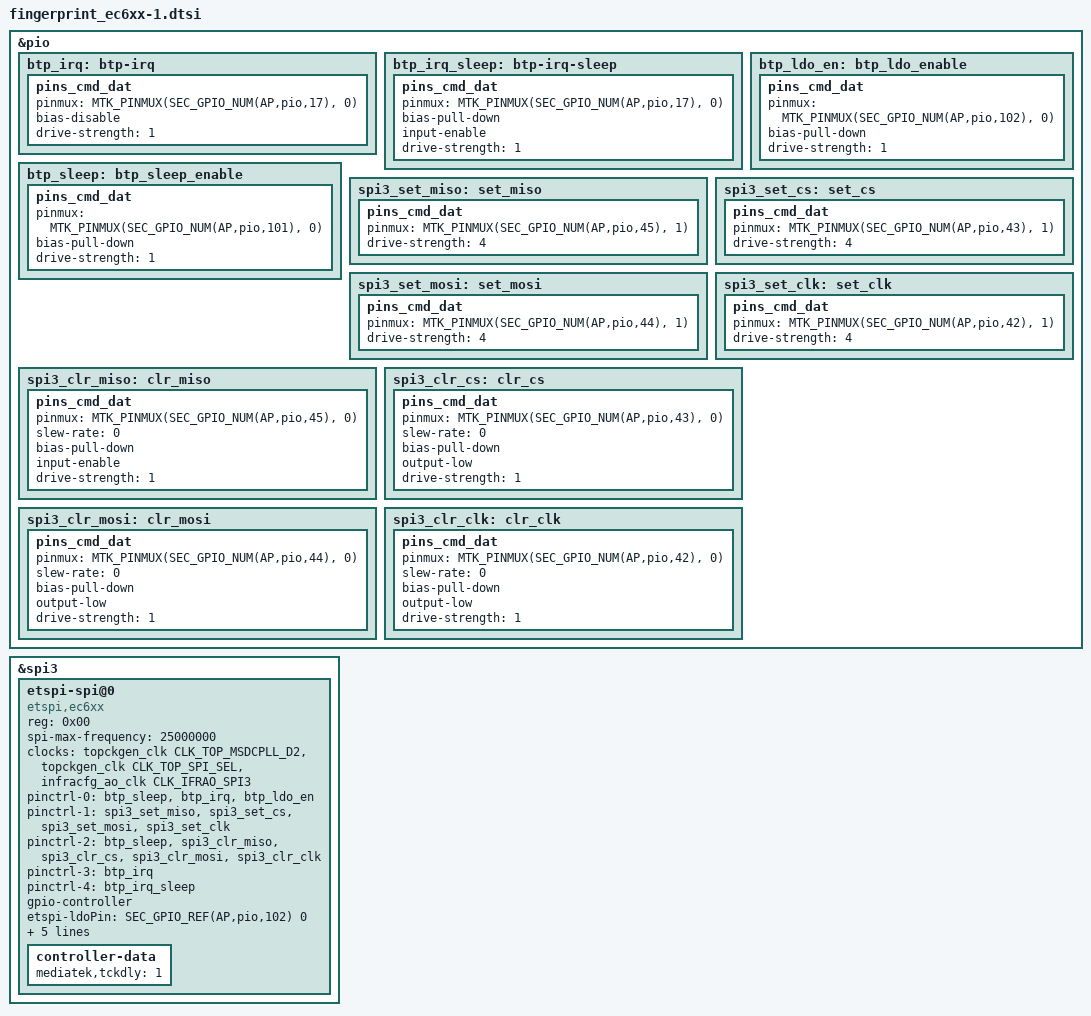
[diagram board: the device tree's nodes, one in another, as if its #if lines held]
/*
 * Copyright (c) 2022, The Linux Foundation. All rights reserved.
 *
 * This program is free software; you can redistribute it and/or modify
 * it under the terms of the GNU General Public License version 2 and
 * only version 2 as published by the Free Software Foundation.
 */

/* drive-strength */
&pio {
	btp_irq: btp-irq {
		pins_cmd_dat{
			pinmux = <MTK_PINMUX(SEC_GPIO_NUM(AP,pio,17), 0)>;
			bias-disable;
			drive-strength = <1>;
		};
	};
	btp_irq_sleep: btp-irq-sleep {
		pins_cmd_dat{
			pinmux = <MTK_PINMUX(SEC_GPIO_NUM(AP,pio,17), 0)>;
			bias-pull-down;
			input-enable;
			drive-strength = <1>;
		};
	};
};
#if 1
&pio {
	btp_ldo_en: btp_ldo_enable {
		pins_cmd_dat{
			pinmux = <MTK_PINMUX(SEC_GPIO_NUM(AP,pio,102), 0)>;
			bias-pull-down;
			drive-strength = <1>;
		};
	};
};
#endif

&pio {
	btp_sleep: btp_sleep_enable {
		pins_cmd_dat{
			pinmux = <MTK_PINMUX(SEC_GPIO_NUM(AP,pio,101), 0)>;
			bias-pull-down;
			drive-strength = <1>;
		};
	};
};

&pio {
	spi3_set_miso: set_miso {
		pins_cmd_dat{
			pinmux = <MTK_PINMUX(SEC_GPIO_NUM(AP,pio,45), 1)>;
			drive-strength = <4>;
		};
	};
	spi3_set_cs: set_cs {
		pins_cmd_dat{
			pinmux = <MTK_PINMUX(SEC_GPIO_NUM(AP,pio,43), 1)>;
			drive-strength = <4>;
		};
	};
	spi3_set_mosi: set_mosi {
		pins_cmd_dat{
			pinmux = <MTK_PINMUX(SEC_GPIO_NUM(AP,pio,44), 1)>;
			drive-strength = <4>;
		};
	};
	spi3_set_clk: set_clk {
		pins_cmd_dat{
			pinmux = <MTK_PINMUX(SEC_GPIO_NUM(AP,pio,42), 1)>;
			drive-strength = <4>;
		};
	};
	spi3_clr_miso: clr_miso {
		pins_cmd_dat{
			pinmux = <MTK_PINMUX(SEC_GPIO_NUM(AP,pio,45), 0)>;
			slew-rate = <0>;
			bias-pull-down;
			input-enable;
			drive-strength = <1>;
		};
	};
	spi3_clr_cs: clr_cs {
		pins_cmd_dat{
			pinmux = <MTK_PINMUX(SEC_GPIO_NUM(AP,pio,43), 0)>;
			slew-rate = <0>;
			bias-pull-down;
			output-low;
			drive-strength = <1>;
		};
	};
	spi3_clr_mosi: clr_mosi {
		pins_cmd_dat{
			pinmux = <MTK_PINMUX(SEC_GPIO_NUM(AP,pio,44), 0)>;
			slew-rate = <0>;
			bias-pull-down;
			output-low;
			drive-strength = <1>;
		};
	};
	spi3_clr_clk: clr_clk {
		pins_cmd_dat{
			pinmux = <MTK_PINMUX(SEC_GPIO_NUM(AP,pio,42), 0)>;
			slew-rate = <0>;
			bias-pull-down;
			output-low;
			drive-strength = <1>;
		};
	};
};
#if 0
&${fps_regul_vdd_3p3} {
    regulator-name = "VDD_BTP_3P3";
    regulator-min-microvolt = <3300000>;
    regulator-max-microvolt = <3300000>;
};
#endif
#if defined(CONFIG_SEC_FACTORY) || !1
&spi3 {
	status = "okay";
#else
&smd {
#endif
	#address-cells = <1>;
	#size-cells = <0>;

	etspi-spi@0 {
		compatible = "etspi,ec6xx";
		reg = <0x00>;
		spi-max-frequency = <25000000>;
#if !defined(CONFIG_SEC_FACTORY) && 1
		clocks = <&topckgen_clk CLK_TOP_MSDCPLL_D2>,
			<&topckgen_clk CLK_TOP_SPI_SEL>,
			<&infracfg_ao_clk CLK_IFRAO_SPI3>;
		clock-names = "parent-clk", "sel-clk", "spi-clk";
#endif
		pinctrl-names = "default", "pins_poweron", "pins_poweroff", "pins_poweron_tz", "pins_poweroff_tz";
#if 1
		pinctrl-0 = <&btp_sleep &btp_irq &btp_ldo_en>;
#else
		pinctrl-0 = <&btp_sleep &btp_irq>;
#endif
		pinctrl-1 = <&spi3_set_miso &spi3_set_cs &spi3_set_mosi &spi3_set_clk>;
		pinctrl-2 = <&btp_sleep &spi3_clr_miso &spi3_clr_cs &spi3_clr_mosi &spi3_clr_clk>;
		pinctrl-3 = <&btp_irq>;
		pinctrl-4 = <&btp_irq_sleep>;
		gpio-controller;
		#gpio-cells = <2>;
#if 1
		etspi-ldoPin = <SEC_GPIO_REF(AP,pio,102) 0>;
#endif
#if 0
		etspi-regulator = "VDD_BTP_3P3";
		VDD_BTP_3P3-supply = <&${fps_regul_vdd_3p3}>;
#endif
		etspi-sleepPin = <SEC_GPIO_REF(AP,pio,101) 0>;
		etspi-drdyPin = <SEC_GPIO_REF(AP,pio,17) 0>;
		etspi-chipid = "EC617";
		etspi-orient = <2>;
		etspi-position = "NA";
		controller-data {
			mediatek,tckdly = <1>;	/* It'll be used after tckdly patch */
		};
	};
};
